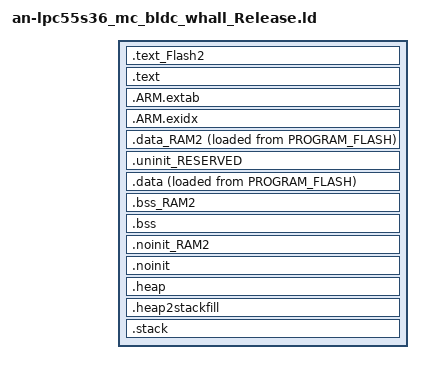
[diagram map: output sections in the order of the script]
/*
 * GENERATED FILE - DO NOT EDIT
 * Copyright 2008-2013 Code Red Technologies Ltd,
 * Copyright 2013-2023 NXP
 * Generated linker script file for LPC55S36
 * Created from linkscript.ldt by FMCreateLinkLibraries
 * Using Freemarker v2.3.30
 * MCUXpresso IDE v11.8.0 [Build 1165] [2023-07-26] on Dec 11, 2023, 2:18:44 PM
 */

INCLUDE "an-lpc55s36_mc_bldc_whall_Release_library.ld"
INCLUDE "an-lpc55s36_mc_bldc_whall_Release_memory.ld"

ENTRY(ResetISR)

SECTIONS
{
     .text_Flash2 : ALIGN(4)
    {
       FILL(0xff)
        *(.text_Flash2) /* for compatibility with previous releases */
        *(.text_QSPI_FLASH) /* for compatibility with previous releases */
        *(.text.$Flash2)
        *(.text.$QSPI_FLASH)
        *(.text_Flash2.*) /* for compatibility with previous releases */
        *(.text_QSPI_FLASH.*) /* for compatibility with previous releases */
        *(.text.$Flash2.*)
        *(.text.$QSPI_FLASH.*)
        *(.rodata.$Flash2)
        *(.rodata.$QSPI_FLASH)
        *(.rodata.$Flash2.*)
        *(.rodata.$QSPI_FLASH.*)            } > QSPI_FLASH

    /* MAIN TEXT SECTION */
    .text : ALIGN(4)
    {
        FILL(0xff)
        __vectors_start__ = ABSOLUTE(.) ;
        KEEP(*(.isr_vector))
        /* Global Section Table */
        . = ALIGN(4) ;
        __section_table_start = .;
        __data_section_table = .;
        LONG(LOADADDR(.data));
        LONG(    ADDR(.data));
        LONG(  SIZEOF(.data));
        LONG(LOADADDR(.data_RAM2));
        LONG(    ADDR(.data_RAM2));
        LONG(  SIZEOF(.data_RAM2));
        __data_section_table_end = .;
        __bss_section_table = .;
        LONG(    ADDR(.bss));
        LONG(  SIZEOF(.bss));
        LONG(    ADDR(.bss_RAM2));
        LONG(  SIZEOF(.bss_RAM2));
        __bss_section_table_end = .;
        __section_table_end = . ;
        /* End of Global Section Table */

        *(.after_vectors*)

       *(.text*)
       *(.rodata .rodata.* .constdata .constdata.*)
       . = ALIGN(4);
    } > PROGRAM_FLASH
    /*
     * for exception handling/unwind - some Newlib functions (in common
     * with C++ and STDC++) use this.
     */
    .ARM.extab : ALIGN(4)
    {
        *(.ARM.extab* .gnu.linkonce.armextab.*)
    } > PROGRAM_FLASH

    .ARM.exidx : ALIGN(4)
    {
        __exidx_start = .;
        *(.ARM.exidx* .gnu.linkonce.armexidx.*)
        __exidx_end = .;
    } > PROGRAM_FLASH
 
    _etext = .;
        
    /* DATA section for SRAMX */

    .data_RAM2 : ALIGN(4)
    {
        FILL(0xff)
        PROVIDE(__start_data_RAM2 = .) ;
        PROVIDE(__start_data_SRAMX = .) ;
        *(.ramfunc.$RAM2)
        *(.ramfunc.$SRAMX)
        *(.data.$RAM2)
        *(.data.$SRAMX)
        *(.data.$RAM2.*)
        *(.data.$SRAMX.*)
        . = ALIGN(4) ;
        PROVIDE(__end_data_RAM2 = .) ;
        PROVIDE(__end_data_SRAMX = .) ;
     } > SRAMX AT>PROGRAM_FLASH

    /* MAIN DATA SECTION */
    .uninit_RESERVED (NOLOAD) : ALIGN(4)
    {
        _start_uninit_RESERVED = .;
        KEEP(*(.bss.$RESERVED*))
       . = ALIGN(4) ;
        _end_uninit_RESERVED = .;
    } > SRAM AT> SRAM

    /* Main DATA section (SRAM) */
    .data : ALIGN(4)
    {
       FILL(0xff)
       _data = . ;
       PROVIDE(__start_data_RAM = .) ;
       PROVIDE(__start_data_SRAM = .) ;
       *(vtable)
       *(.ramfunc*)
       KEEP(*(CodeQuickAccess))
       KEEP(*(DataQuickAccess))
       *(RamFunction)
       *(.data*)
       . = ALIGN(4) ;
       _edata = . ;
       PROVIDE(__end_data_RAM = .) ;
       PROVIDE(__end_data_SRAM = .) ;
    } > SRAM AT>PROGRAM_FLASH

    /* BSS section for SRAMX */
    .bss_RAM2 (NOLOAD) : ALIGN(4)
    {
       PROVIDE(__start_bss_RAM2 = .) ;
       PROVIDE(__start_bss_SRAMX = .) ;
       *(.bss.$RAM2)
       *(.bss.$SRAMX)
       *(.bss.$RAM2.*)
       *(.bss.$SRAMX.*)
       . = ALIGN (. != 0 ? 4 : 1) ; /* avoid empty segment */
       PROVIDE(__end_bss_RAM2 = .) ;
       PROVIDE(__end_bss_SRAMX = .) ;
    } > SRAMX AT> SRAMX

    /* MAIN BSS SECTION */
    .bss (NOLOAD) : ALIGN(4)
    {
        _bss = .;
        PROVIDE(__start_bss_RAM = .) ;
        PROVIDE(__start_bss_SRAM = .) ;
        *(.bss*)
        *(COMMON)
        . = ALIGN(4) ;
        _ebss = .;
        PROVIDE(__end_bss_RAM = .) ;
        PROVIDE(__end_bss_SRAM = .) ;
        PROVIDE(end = .);
    } > SRAM AT> SRAM

    /* NOINIT section for SRAMX */
    .noinit_RAM2 (NOLOAD) : ALIGN(4)
    {
       PROVIDE(__start_noinit_RAM2 = .) ;
       PROVIDE(__start_noinit_SRAMX = .) ;
       *(.noinit.$RAM2)
       *(.noinit.$SRAMX)
       *(.noinit.$RAM2.*)
       *(.noinit.$SRAMX.*)
       . = ALIGN(4) ;
       PROVIDE(__end_noinit_RAM2 = .) ;
       PROVIDE(__end_noinit_SRAMX = .) ;
    } > SRAMX AT> SRAMX

    /* DEFAULT NOINIT SECTION */
    .noinit (NOLOAD): ALIGN(4)
    {
        _noinit = .;
        PROVIDE(__start_noinit_RAM = .) ;
        PROVIDE(__start_noinit_SRAM = .) ;
        *(.noinit*)
         . = ALIGN(4) ;
        _end_noinit = .;
       PROVIDE(__end_noinit_RAM = .) ;
       PROVIDE(__end_noinit_SRAM = .) ;        
    } > SRAM AT> SRAM

    /* Reserve and place Heap within memory map */
    _HeapSize = 0x1000;
    .heap (NOLOAD) :  ALIGN(4)
    {
        _pvHeapStart = .;
        . += _HeapSize;
        . = ALIGN(4);
        _pvHeapLimit = .;
    } > SRAM

     _StackSize = 0x1000;
     /* Reserve space in memory for Stack */
    .heap2stackfill (NOLOAD) :
    {
        . += _StackSize;
    } > SRAM
    /* Locate actual Stack in memory map */
    .stack ORIGIN(SRAM) + LENGTH(SRAM) - _StackSize - 0 (NOLOAD) :  ALIGN(4)
    {
        _vStackBase = .;
        . = ALIGN(4);
        _vStackTop = . + _StackSize;
    } > SRAM

    /* ## Create checksum value (used in startup) ## */
    PROVIDE(__valid_user_code_checksum = 0 - 
                                         (_vStackTop 
                                         + (ResetISR + 1) 
                                         + (NMI_Handler + 1) 
                                         + (HardFault_Handler + 1) 
                                         + (( DEFINED(MemManage_Handler) ? MemManage_Handler : 0 ) + 1)   /* MemManage_Handler may not be defined */
                                         + (( DEFINED(BusFault_Handler) ? BusFault_Handler : 0 ) + 1)     /* BusFault_Handler may not be defined */
                                         + (( DEFINED(UsageFault_Handler) ? UsageFault_Handler : 0 ) + 1) /* UsageFault_Handler may not be defined */
                                         ) );

    /* Provide basic symbols giving location and size of main text
     * block, including initial values of RW data sections. Note that
     * these will need extending to give a complete picture with
     * complex images (e.g multiple Flash banks).
     */
    _image_start = LOADADDR(.text);
    _image_end = LOADADDR(.data) + SIZEOF(.data);
    _image_size = _image_end - _image_start;
}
